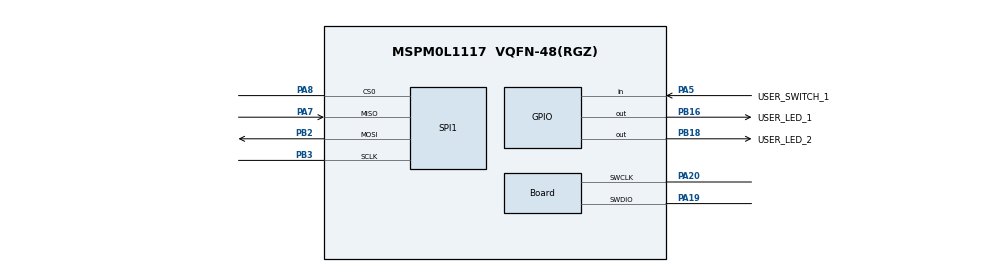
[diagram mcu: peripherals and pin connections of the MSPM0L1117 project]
// @cliArgs --device "MSPM0L111X" --package "VQFN-48(RGZ)" --part "Default"
// @v2CliArgs --device "MSPM0L1117" --package "VQFN-48(RGZ)"
// @cliArgs --board /ti/boards/LP_MSPM0L1117 --rtos nortos

/**
 * Import the modules used in this configuration.
 */
const GPIO          = scripting.addModule("/ti/driverlib/GPIO", {}, false);
const GPIO1         = GPIO.addInstance();
const GPIO2         = GPIO.addInstance();
const SPI           = scripting.addModule("/ti/driverlib/SPI", {}, false);
const SPI1          = SPI.addInstance();
const ProjectConfig = scripting.addModule("/ti/project_config/ProjectConfig");

/**
 * Write custom configuration values to the imported modules.
 */
GPIO1.$name                          = "GPIO_LEDS";
GPIO1.associatedPins.create(2);
GPIO1.associatedPins[0].$name        = "USER_LED_1";
GPIO1.associatedPins[0].assignedPort = "PORTB";
GPIO1.associatedPins[0].assignedPin  = "16";
GPIO1.associatedPins[0].pin.$assign  = "PB16";
GPIO1.associatedPins[1].$name        = "USER_LED_2";
GPIO1.associatedPins[1].assignedPort = "PORTB";
GPIO1.associatedPins[1].assignedPin  = "18";
GPIO1.associatedPins[1].pin.$assign  = "PB18";

const Board                       = scripting.addModule("/ti/driverlib/Board", {}, false);
Board.peripheral.$assign          = "DEBUGSS";
Board.peripheral.swclkPin.$assign = "PA20";
Board.peripheral.swdioPin.$assign = "PA19";

GPIO2.$name                          = "GPIO_SWITCHES";
GPIO2.associatedPins[0].direction    = "INPUT";
GPIO2.associatedPins[0].interruptEn  = true;
GPIO2.associatedPins[0].$name        = "USER_SWITCH_1";
GPIO2.associatedPins[0].polarity     = "RISE";
GPIO2.associatedPins[0].assignedPort = "PORTA";
GPIO2.associatedPins[0].assignedPin  = "5";
GPIO2.associatedPins[0].pin.$assign  = "PA5";

SPI1.$name                              = "SPI_0";
SPI1.mode                               = "PERIPHERAL";
SPI1.rxFifoThreshold                    = "DL_SPI_RX_FIFO_LEVEL_ONE_FRAME";
SPI1.enabledInterrupts                  = ["RX"];
SPI1.peripheral.$assign                 = "SPI0";
SPI1.peripheral.sclkPin.$assign         = "PB3";
SPI1.peripheral.mosiPin.$assign         = "PB2";
SPI1.peripheral.misoPin.$assign         = "PA7";
SPI1.peripheral.cs0Pin.$assign          = "PA8";

const SYSCTL              = scripting.addModule("/ti/driverlib/SYSCTL", {}, false);
SYSCTL.peripheral.$assign = "SYSCTL";

ProjectConfig.migrationCondition = true;
